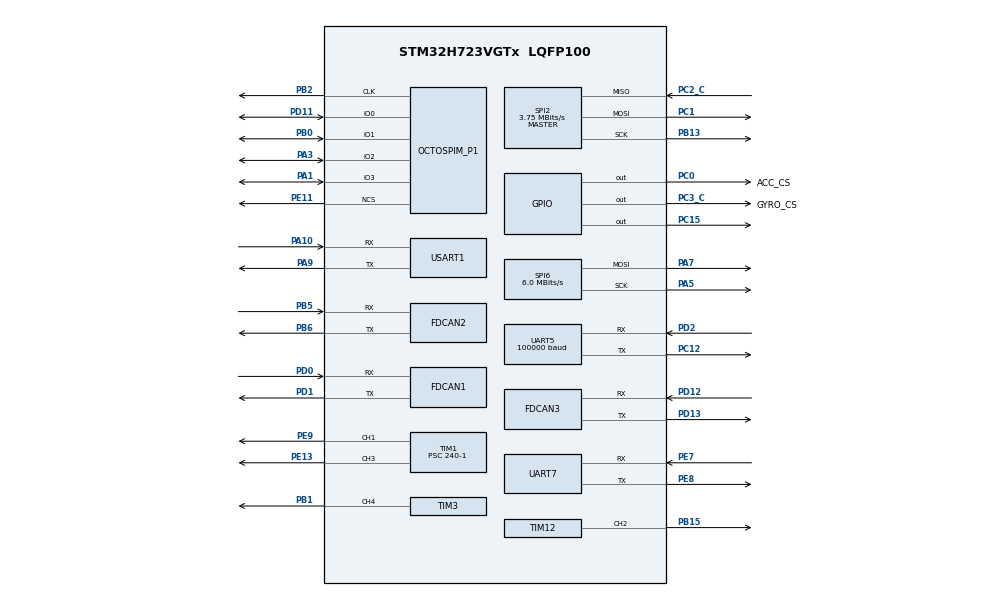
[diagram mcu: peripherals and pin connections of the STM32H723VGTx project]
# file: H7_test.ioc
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CORTEX_M7.CPU_DCache=Disabled
CORTEX_M7.CPU_ICache=Enabled
CORTEX_M7.MPU_Control=__NULL
CORTEX_M7.default_mode_Activation=0
Dma.Request0=UART5_RX
Dma.Request1=USART1_RX
Dma.Request2=UART7_TX
Dma.UART5_RX.0.Direction=DMA_PERIPH_TO_MEMORY
Dma.UART5_RX.0.EventEnable=DISABLE
Dma.UART5_RX.0.FIFOMode=DMA_FIFOMODE_DISABLE
Dma.UART5_RX.0.Instance=DMA1_Stream5
Dma.UART5_RX.0.MemDataAlignment=DMA_MDATAALIGN_BYTE
Dma.UART5_RX.0.MemInc=DMA_MINC_ENABLE
Dma.UART5_RX.0.Mode=DMA_NORMAL
Dma.UART5_RX.0.PeriphDataAlignment=DMA_PDATAALIGN_BYTE
Dma.UART5_RX.0.PeriphInc=DMA_PINC_DISABLE
Dma.UART5_RX.0.Polarity=HAL_DMAMUX_REQ_GEN_RISING
Dma.UART5_RX.0.Priority=DMA_PRIORITY_LOW
Dma.UART5_RX.0.RequestNumber=1
Dma.UART5_RX.0.SignalID=NONE
Dma.UART5_RX.0.SyncEnable=DISABLE
Dma.UART5_RX.0.SyncPolarity=HAL_DMAMUX_SYNC_NO_EVENT
Dma.UART5_RX.0.SyncRequestNumber=1
Dma.UART5_RX.0.SyncSignalID=NONE
Dma.UART7_TX.2.Direction=DMA_MEMORY_TO_PERIPH
Dma.UART7_TX.2.EventEnable=DISABLE
Dma.UART7_TX.2.FIFOMode=DMA_FIFOMODE_DISABLE
Dma.UART7_TX.2.Instance=DMA1_Stream2
Dma.UART7_TX.2.MemDataAlignment=DMA_MDATAALIGN_BYTE
Dma.UART7_TX.2.MemInc=DMA_MINC_ENABLE
Dma.UART7_TX.2.Mode=DMA_NORMAL
Dma.UART7_TX.2.PeriphDataAlignment=DMA_PDATAALIGN_BYTE
Dma.UART7_TX.2.PeriphInc=DMA_PINC_DISABLE
Dma.UART7_TX.2.Polarity=HAL_DMAMUX_REQ_GEN_RISING
Dma.UART7_TX.2.Priority=DMA_PRIORITY_HIGH
Dma.UART7_TX.2.RequestNumber=1
Dma.UART7_TX.2.SignalID=NONE
Dma.UART7_TX.2.SyncEnable=DISABLE
Dma.UART7_TX.2.SyncPolarity=HAL_DMAMUX_SYNC_NO_EVENT
Dma.UART7_TX.2.SyncRequestNumber=1
Dma.UART7_TX.2.SyncSignalID=NONE
Dma.USART1_RX.1.Direction=DMA_PERIPH_TO_MEMORY
Dma.USART1_RX.1.EventEnable=DISABLE
Dma.USART1_RX.1.FIFOMode=DMA_FIFOMODE_DISABLE
Dma.USART1_RX.1.Instance=DMA2_Stream1
Dma.USART1_RX.1.MemDataAlignment=DMA_MDATAALIGN_BYTE
Dma.USART1_RX.1.MemInc=DMA_MINC_ENABLE
Dma.USART1_RX.1.Mode=DMA_NORMAL
Dma.USART1_RX.1.PeriphDataAlignment=DMA_PDATAALIGN_BYTE
Dma.USART1_RX.1.PeriphInc=DMA_PINC_DISABLE
Dma.USART1_RX.1.Polarity=HAL_DMAMUX_REQ_GEN_RISING
Dma.USART1_RX.1.Priority=DMA_PRIORITY_HIGH
Dma.USART1_RX.1.RequestNumber=1
Dma.USART1_RX.1.SignalID=NONE
Dma.USART1_RX.1.SyncEnable=DISABLE
Dma.USART1_RX.1.SyncPolarity=HAL_DMAMUX_SYNC_NO_EVENT
Dma.USART1_RX.1.SyncRequestNumber=1
Dma.USART1_RX.1.SyncSignalID=NONE
FDCAN1.CalculateBaudRateNominal=1000000
FDCAN1.CalculateTimeBitNominal=1000
FDCAN1.CalculateTimeQuantumNominal=200.0
FDCAN1.Mode=FDCAN_MODE_NORMAL
FDCAN1.NominalPrescaler=24
FDCAN1.RxFifo0ElmtsNbr=32
FDCAN1.StdFiltersNbr=1
FDCAN1.TxFifoQueueElmtsNbr=32
FDCAN2.CalculateBaudRateNominal=1000000
FDCAN2.CalculateTimeBitNominal=1000
FDCAN2.CalculateTimeQuantumNominal=200.0
FDCAN2.MessageRAMOffset=0x406
FDCAN2.NominalPrescaler=24
FDCAN2.RxFifo0ElmtsNbr=32
FDCAN2.StdFiltersNbr=1
FDCAN2.TxFifoQueueElmtsNbr=32
FDCAN3.CalculateBaudRateNominal=1000000
FDCAN3.CalculateTimeBitNominal=1000
FDCAN3.CalculateTimeQuantumNominal=200.0
FDCAN3.MessageRAMOffset=0x812
FDCAN3.NominalPrescaler=24
FDCAN3.RxFifo0ElmtsNbr=32
FDCAN3.StdFiltersNbr=1
FDCAN3.TxFifoQueueElmtsNbr=32
FREERTOS.Tasks01=defaultTask,24,64,StartDefaultTask,Default,NULL,Dynamic,NULL,NULL;Ws2812_task,9,64,ws2812_task,As external,NULL,Dynamic,NULL,NULL;INS_task,11,128,ins_task,As external,NULL,Dynamic,NULL,NULL;BUZZER_task,9,64,buzzer_task,As external,NULL,Dynamic,NULL,NULL;CK_TIMEOUT_TASK,9,64,CK_Timeout_task,As external,NULL,Dynamic,NULL,NULL;CP_TASK,11,128,CP_task,As external,NULL,Dynamic,NULL,NULL;GYM_TASK,13,256,Gym_task,As external,NULL,Dynamic,NULL,NULL;UI_TASK,12,128,UI_task,As external,NULL,Dynamic,NULL,NULL;SERVER_TASK,12,64,Servos_task,As external,NULL,Dynamic,NULL,NULL
FREERTOS.configENABLE_FPU=1
FREERTOS.configMINIMAL_STACK_SIZE=0x40
FREERTOS.configUSE_OS2_MUTEX=0
FREERTOS.configUSE_OS2_TIMER=0
Mcu.Family=STM32H7
Mcu.Name=STM32H723VGTx
Mcu.Package=LQFP100
NVIC.DMA1_Stream2_IRQn=true\:5\:0\:false\:false\:true\:false\:false\:true\:true
NVIC.DMA1_Stream5_IRQn=true\:0\:0\:false\:false\:true\:false\:false\:true\:true
NVIC.DMA2_Stream1_IRQn=true\:0\:0\:false\:false\:true\:false\:false\:true\:true
NVIC.FDCAN1_IT0_IRQn=true\:1\:0\:true\:false\:true\:false\:true\:true\:true
NVIC.FDCAN1_IT1_IRQn=true\:1\:0\:true\:false\:true\:false\:true\:true\:true
NVIC.FDCAN2_IT0_IRQn=true\:1\:0\:true\:false\:true\:false\:true\:true\:true
NVIC.FDCAN2_IT1_IRQn=true\:1\:0\:true\:false\:true\:false\:true\:true\:true
NVIC.FDCAN3_IT0_IRQn=true\:1\:0\:true\:false\:true\:false\:true\:true\:true
NVIC.FDCAN3_IT1_IRQn=true\:1\:0\:true\:false\:true\:false\:true\:true\:true
NVIC.PriorityGroup=NVIC_PRIORITYGROUP_4
NVIC.TIM23_IRQn=true\:15\:0\:false\:false\:true\:false\:false\:true\:true
NVIC.TimeBase=TIM23_IRQn
NVIC.TimeBaseIP=TIM23
NVIC.UART5_IRQn=true\:1\:0\:true\:false\:true\:false\:true\:true\:true
NVIC.USART1_IRQn=true\:1\:0\:true\:false\:true\:false\:true\:true\:true
OCTOSPI2.ClockMode=HAL_OSPI_CLOCK_MODE_3
OCTOSPI2.ClockPrescaler=3
OCTOSPI2.DeviceSize=23
OCTOSPI2.DeviceType=SPI_DEVICE_FLASH
OCTOSPI2.FifoThreshold=8
OCTOSPI2.SampleShifting=HAL_OSPI_SAMPLE_SHIFTING_HALFCYCLE
PA1.Mode=OCTOSPI2_IOL_Port1L
PA1.Signal=OCTOSPIM_P1_IO3
PA10.GPIO_PuPd=GPIO_PULLUP
PA10.GPIO_Speed=GPIO_SPEED_FREQ_HIGH
PA10.Mode=Asynchronous
PA10.Signal=USART1_RX
PA13(JTMS/SWDIO).Mode=Serial_Wire
PA13(JTMS/SWDIO).Signal=DEBUG_JTMS-SWDIO
PA14(JTCK/SWCLK).Mode=Serial_Wire
PA14(JTCK/SWCLK).Signal=DEBUG_JTCK-SWCLK
PA3.Mode=OCTOSPI2_IOL_Port1L
PA3.Signal=OCTOSPIM_P1_IO2
PA5.GPIO_Speed=GPIO_SPEED_FREQ_VERY_HIGH
PA5.Mode=TX_Only_Simplex_Unidirect_Master
PA5.Signal=SPI6_SCK
PA7.GPIO_Speed=GPIO_SPEED_FREQ_VERY_HIGH
PA7.Mode=TX_Only_Simplex_Unidirect_Master
PA7.Signal=SPI6_MOSI
PA9.GPIO_PuPd=GPIO_PULLUP
PA9.GPIO_Speed=GPIO_SPEED_FREQ_HIGH
PA9.Mode=Asynchronous
PA9.Signal=USART1_TX
PB0.Mode=OCTOSPI2_IOL_Port1L
PB0.Signal=OCTOSPIM_P1_IO1
PB1.Signal=S_TIM3_CH4
PB13.GPIO_Speed=GPIO_SPEED_FREQ_VERY_HIGH
PB13.Mode=Full_Duplex_Master
PB13.Signal=SPI2_SCK
PB15.GPIO_Speed=GPIO_SPEED_FREQ_VERY_HIGH
PB15.Signal=S_TIM12_CH2
PB2.Mode=O2_P1_CLK
PB2.Signal=OCTOSPIM_P1_CLK
PB5.Mode=FDCAN_Activate
PB5.Signal=FDCAN2_RX
PB6.Mode=FDCAN_Activate
PB6.Signal=FDCAN2_TX
PC0.GPIO_Label=ACC_CS
PC0.GPIO_Speed=GPIO_SPEED_FREQ_VERY_HIGH
PC0.PinState=GPIO_PIN_SET
PC0.Signal=GPIO_Output
PC1.GPIO_Speed=GPIO_SPEED_FREQ_VERY_HIGH
PC1.Mode=Full_Duplex_Master
PC1.Signal=SPI2_MOSI
PC12.Mode=Asynchronous
PC12.Signal=UART5_TX
PC15-OSC32_OUT.Signal=GPIO_Output
PC2_C.GPIO_Speed=GPIO_SPEED_FREQ_VERY_HIGH
PC2_C.Mode=Full_Duplex_Master
PC2_C.Signal=SPI2_MISO
PC3_C.GPIO_Label=GYRO_CS
PC3_C.GPIO_Speed=GPIO_SPEED_FREQ_VERY_HIGH
PC3_C.PinState=GPIO_PIN_SET
PC3_C.Signal=GPIO_Output
PD0.GPIO_Speed=GPIO_SPEED_FREQ_VERY_HIGH
PD0.Mode=FDCAN_Activate
PD0.Signal=FDCAN1_RX
PD1.GPIO_Speed=GPIO_SPEED_FREQ_VERY_HIGH
PD1.Mode=FDCAN_Activate
PD1.Signal=FDCAN1_TX
PD11.Mode=OCTOSPI2_IOL_Port1L
PD11.Signal=OCTOSPIM_P1_IO0
PD12.Mode=FDCAN_Activate
PD12.Signal=FDCAN3_RX
PD13.Mode=FDCAN_Activate
PD13.Signal=FDCAN3_TX
PD2.GPIO_Speed=GPIO_SPEED_FREQ_LOW
PD2.Mode=Asynchronous
PD2.Signal=UART5_RX
PE11.Mode=OCTOSPI2_Port1_NCS
PE11.Signal=OCTOSPIM_P1_NCS
PE13.Signal=S_TIM1_CH3
PE7.Mode=Asynchronous
PE7.Signal=UART7_RX
PE8.Mode=Asynchronous
PE8.Signal=UART7_TX
PE9.Signal=S_TIM1_CH1
PH0-OSC_IN.Mode=HSE-External-Oscillator
PH0-OSC_IN.Signal=RCC_OSC_IN
PH1-OSC_OUT.Mode=HSE-External-Oscillator
PH1-OSC_OUT.Signal=RCC_OSC_OUT
ProjectManager.HeapSize=0x200
ProjectManager.StackSize=0x800
ProjectManager.TargetToolchain=MDK-ARM V5.27
RCC.ADCFreq_Value=48375000
RCC.APB1Freq_Value=120000000
RCC.APB2Freq_Value=120000000
RCC.APB3Freq_Value=120000000
RCC.APB4Freq_Value=120000000
RCC.CortexFreq_Value=480000000
RCC.D1PPRE=RCC_APB3_DIV2
RCC.D2PPRE1=RCC_APB1_DIV2
RCC.D2PPRE2=RCC_APB2_DIV2
RCC.D3PPRE=RCC_APB4_DIV2
RCC.DIVM1=2
RCC.DIVN1=40
RCC.DIVP1=1
RCC.DIVQ1=4
RCC.EnbaleCSS=true
RCC.HCLKFreq_Value=240000000
RCC.HPRE=RCC_HCLK_DIV2
RCC.HSE_VALUE=24000000
RCC.PLL3FRACN=0
RCC.PLLFRACN=0
RCC.PLLSourceVirtual=RCC_PLLSOURCE_HSE
RCC.SPI6CLockSelection=RCC_SPI6CLKSOURCE_HSE
RCC.SYSCLKFreq_VALUE=480000000
RCC.SYSCLKSource=RCC_SYSCLKSOURCE_PLLCLK
RCC.USBFreq_Value=120000000
SH.S_TIM12_CH2.0=TIM12_CH2,PWM Generation2 CH2
SH.S_TIM1_CH1.0=TIM1_CH1,PWM Generation1 CH1
SH.S_TIM1_CH3.0=TIM1_CH3,PWM Generation3 CH3
SH.S_TIM3_CH4.0=TIM3_CH4,PWM Generation4 CH4
SPI2.BaudRatePrescaler=SPI_BAUDRATEPRESCALER_32
SPI2.CLKPhase=SPI_PHASE_2EDGE
SPI2.CLKPolarity=SPI_POLARITY_HIGH
SPI2.CalculateBaudRate=3.75 MBits/s
SPI2.DataSize=SPI_DATASIZE_8BIT
SPI2.Direction=SPI_DIRECTION_2LINES
SPI2.Mode=SPI_MODE_MASTER
SPI2.VirtualType=VM_MASTER
SPI6.BaudRatePrescaler=SPI_BAUDRATEPRESCALER_4
SPI6.CLKPhase=SPI_PHASE_2EDGE
SPI6.CalculateBaudRate=6.0 MBits/s
SPI6.DataSize=SPI_DATASIZE_8BIT
SPI6.Direction=SPI_DIRECTION_2LINES_TXONLY
SPI6.Mode=SPI_MODE_MASTER
SPI6.VirtualType=VM_MASTER
TIM1.Channel-PWM\ Generation1\ CH1=TIM_CHANNEL_1
TIM1.Channel-PWM\ Generation3\ CH3=TIM_CHANNEL_3
TIM1.Period=20000-1
TIM1.Prescaler=240-1
TIM12.Channel-PWM\ Generation2\ CH2=TIM_CHANNEL_2
TIM12.Period=2000-1
TIM12.Prescaler=128-1
TIM3.AutoReloadPreload=TIM_AUTORELOAD_PRELOAD_ENABLE
TIM3.Channel-PWM\ Generation4\ CH4=TIM_CHANNEL_4
TIM3.Period=10000-1
TIM3.Prescaler=24-1
UART5.BaudRate=100000
UART5.Mode=MODE_RX
UART5.Parity=PARITY_EVEN
UART5.StopBits=UART_STOPBITS_2
UART5.WordLength=WORDLENGTH_9B
USART1.VirtualMode-Asynchronous=VM_ASYNC
VP_FREERTOS_VS_CMSIS_V2.Mode=CMSIS_V2
VP_OCTOSPI2_VS_quad.Mode=quad_mode
VP_SYS_VS_tim23.Mode=TIM23
board=custom

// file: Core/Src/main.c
/* USER CODE BEGIN Header */
/**
  ******************************************************************************
  * @file           : main.c
  * @brief          : Main program body
  ******************************************************************************
  * @attention
  *
  * Copyright (c) 2024 STMicroelectronics.
  * All rights reserved.
  *
  * This software is licensed under terms that can be found in the LICENSE file
  * in the root directory of this software component.
  * If no LICENSE file comes with this software, it is provided AS-IS.
  *
  ******************************************************************************
  */
/* USER CODE END Header */
#include "main.h"
#include "cmsis_os.h"
#include "dma.h"
#include "fdcan.h"
#include "octospi.h"
#include "spi.h"
#include "tim.h"
#include "usart.h"
#include "gpio.h"

/* USER CODE BEGIN Includes */
#include "BSP_CAN.h"
#include "REMOTE_task.h"
#include "cp_usart.h"
/* USER CODE END Includes */

void SystemClock_Config(void);
void MX_FREERTOS_Init(void);
/* USER CODE BEGIN PFP */
extern uint8_t usart3_rx_data_buf[REMOTE_RECEVER_LEN+5];
extern uint8_t uart6_rx_data_buf[USART6_DMA_RX_DATA_LEN];
/* USER CODE END PFP */

int main(void)
{

  /* Enable the CPU Cache */

  /* Enable I-Cache---------------------------------------------------------*/
  SCB_EnableICache();

  /* MCU Configuration--------------------------------------------------------*/

  /* Reset of all peripherals, Initializes the Flash interface and the Systick. */
  HAL_Init();

  /* Configure the system clock */
  SystemClock_Config();

  /* Initialize all configured peripherals */
  MX_GPIO_Init();
  MX_DMA_Init();
  MX_OCTOSPI2_Init();
  MX_FDCAN1_Init();
  MX_FDCAN2_Init();
  MX_FDCAN3_Init();
  MX_SPI2_Init();
  MX_TIM3_Init();
  MX_TIM12_Init();
  MX_SPI6_Init();
  MX_UART5_Init();
  MX_USART1_UART_Init();
  MX_TIM1_Init();
  MX_UART7_Init();
  /* USER CODE BEGIN 2 */
  while(HAL_UARTEx_ReceiveToIdle_DMA(&huart1,uart6_rx_data_buf,USART6_DMA_RX_DATA_LEN) != HAL_OK);  // 串口1 DMA 开启接受（裁判系统）
  can_bsp_init();
  HAL_UARTEx_ReceiveToIdle_DMA(&huart5,usart3_rx_data_buf,REMOTE_RECEVER_LEN);    // 串口5 DMA 开始接受（遥控器）

  /* USER CODE END 2 */

  /* Init scheduler */
  osKernelInitialize();

  /* Call init function for freertos objects (in cmsis_os2.c) */
  MX_FREERTOS_Init();

  /* Start scheduler */
  osKernelStart();

  /* We should never get here as control is now taken by the scheduler */

  /* Infinite loop */
  while (1)
  {

  }
}

void SystemClock_Config(void)
{
  RCC_OscInitTypeDef RCC_OscInitStruct = {0};
  RCC_ClkInitTypeDef RCC_ClkInitStruct = {0};

  /** Supply configuration update enable
  */
  HAL_PWREx_ConfigSupply(PWR_LDO_SUPPLY);

  /** Configure the main internal regulator output voltage
  */
  __HAL_PWR_VOLTAGESCALING_CONFIG(PWR_REGULATOR_VOLTAGE_SCALE0);

  while(!__HAL_PWR_GET_FLAG(PWR_FLAG_VOSRDY)) {}

  /** Initializes the RCC Oscillators according to the specified parameters
  * in the RCC_OscInitTypeDef structure.
  */
  RCC_OscInitStruct.OscillatorType = RCC_OSCILLATORTYPE_HSE;
  RCC_OscInitStruct.HSEState = RCC_HSE_ON;
  RCC_OscInitStruct.PLL.PLLState = RCC_PLL_ON;
  RCC_OscInitStruct.PLL.PLLSource = RCC_PLLSOURCE_HSE;
  RCC_OscInitStruct.PLL.PLLM = 2;
  RCC_OscInitStruct.PLL.PLLN = 40;
  RCC_OscInitStruct.PLL.PLLP = 1;
  RCC_OscInitStruct.PLL.PLLQ = 4;
  RCC_OscInitStruct.PLL.PLLR = 2;
  RCC_OscInitStruct.PLL.PLLRGE = RCC_PLL1VCIRANGE_3;
  RCC_OscInitStruct.PLL.PLLVCOSEL = RCC_PLL1VCOWIDE;
  RCC_OscInitStruct.PLL.PLLFRACN = 0;
  if (HAL_RCC_OscConfig(&RCC_OscInitStruct) != HAL_OK)
  {
    Error_Handler();
  }

  /** Initializes the CPU, AHB and APB buses clocks
  */
  RCC_ClkInitStruct.ClockType = RCC_CLOCKTYPE_HCLK|RCC_CLOCKTYPE_SYSCLK
                              |RCC_CLOCKTYPE_PCLK1|RCC_CLOCKTYPE_PCLK2
                              |RCC_CLOCKTYPE_D3PCLK1|RCC_CLOCKTYPE_D1PCLK1;
  RCC_ClkInitStruct.SYSCLKSource = RCC_SYSCLKSOURCE_PLLCLK;
  RCC_ClkInitStruct.SYSCLKDivider = RCC_SYSCLK_DIV1;
  RCC_ClkInitStruct.AHBCLKDivider = RCC_HCLK_DIV2;
  RCC_ClkInitStruct.APB3CLKDivider = RCC_APB3_DIV2;
  RCC_ClkInitStruct.APB1CLKDivider = RCC_APB1_DIV2;
  RCC_ClkInitStruct.APB2CLKDivider = RCC_APB2_DIV2;
  RCC_ClkInitStruct.APB4CLKDivider = RCC_APB4_DIV2;

  if (HAL_RCC_ClockConfig(&RCC_ClkInitStruct, FLASH_LATENCY_3) != HAL_OK)
  {
    Error_Handler();
  }

  /** Enables the Clock Security System
  */
  HAL_RCC_EnableCSS();
}

void HAL_TIM_PeriodElapsedCallback(TIM_HandleTypeDef *htim)
{
  if (htim->Instance == TIM23) {
    HAL_IncTick();
  }
}

void Error_Handler(void)
{
  __disable_irq();
  while (1)
  {
  }
}

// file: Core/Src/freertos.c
/* USER CODE BEGIN Header */
/**
  ******************************************************************************
  * File Name          : freertos.c
  * Description        : Code for freertos applications
  ******************************************************************************
  * @attention
  *
  * Copyright (c) 2024 STMicroelectronics.
  * All rights reserved.
  *
  * This software is licensed under terms that can be found in the LICENSE file
  * in the root directory of this software component.
  * If no LICENSE file comes with this software, it is provided AS-IS.
  *
  ******************************************************************************
  */
/* USER CODE END Header */

#include "FreeRTOS.h"
#include "task.h"
#include "main.h"
#include "cmsis_os.h"

/* USER CODE BEGIN Includes */
#include "WS2812_task.h"

/* USER CODE END Includes */

/* Definitions for defaultTask */
osThreadId_t defaultTaskHandle;
const osThreadAttr_t defaultTask_attributes = {
  .name = "defaultTask",
  .stack_size = 64 * 4,
  .priority = (osPriority_t) osPriorityNormal,
};
/* Definitions for Ws2812_task */
osThreadId_t Ws2812_taskHandle;
const osThreadAttr_t Ws2812_task_attributes = {
  .name = "Ws2812_task",
  .stack_size = 64 * 4,
  .priority = (osPriority_t) osPriorityLow1,
};
/* Definitions for INS_task */
osThreadId_t INS_taskHandle;
const osThreadAttr_t INS_task_attributes = {
  .name = "INS_task",
  .stack_size = 128 * 4,
  .priority = (osPriority_t) osPriorityLow3,
};
/* Definitions for BUZZER_task */
osThreadId_t BUZZER_taskHandle;
const osThreadAttr_t BUZZER_task_attributes = {
  .name = "BUZZER_task",
  .stack_size = 64 * 4,
  .priority = (osPriority_t) osPriorityLow1,
};
/* Definitions for CK_TIMEOUT_TASK */
osThreadId_t CK_TIMEOUT_TASKHandle;
const osThreadAttr_t CK_TIMEOUT_TASK_attributes = {
  .name = "CK_TIMEOUT_TASK",
  .stack_size = 64 * 4,
  .priority = (osPriority_t) osPriorityLow1,
};
/* Definitions for CP_TASK */
osThreadId_t CP_TASKHandle;
const osThreadAttr_t CP_TASK_attributes = {
  .name = "CP_TASK",
  .stack_size = 128 * 4,
  .priority = (osPriority_t) osPriorityLow3,
};
/* Definitions for GYM_TASK */
osThreadId_t GYM_TASKHandle;
const osThreadAttr_t GYM_TASK_attributes = {
  .name = "GYM_TASK",
  .stack_size = 256 * 4,
  .priority = (osPriority_t) osPriorityLow5,
};
/* Definitions for UI_TASK */
osThreadId_t UI_TASKHandle;
const osThreadAttr_t UI_TASK_attributes = {
  .name = "UI_TASK",
  .stack_size = 128 * 4,
  .priority = (osPriority_t) osPriorityLow4,
};
/* Definitions for SERVER_TASK */
osThreadId_t SERVER_TASKHandle;
const osThreadAttr_t SERVER_TASK_attributes = {
  .name = "SERVER_TASK",
  .stack_size = 64 * 4,
  .priority = (osPriority_t) osPriorityLow4,
};

void StartDefaultTask(void *argument);
extern void ws2812_task(void *argument);
extern void ins_task(void *argument);
extern void buzzer_task(void *argument);
extern void CK_Timeout_task(void *argument);
extern void CP_task(void *argument);
extern void Gym_task(void *argument);
extern void UI_task(void *argument);
extern void Servos_task(void *argument);

void MX_FREERTOS_Init(void); /* (MISRA C 2004 rule 8.1) */

void MX_FREERTOS_Init(void) {

  /* Create the thread(s) */
  /* creation of defaultTask */
  defaultTaskHandle = osThreadNew(StartDefaultTask, NULL, &defaultTask_attributes);

  /* creation of Ws2812_task */
  Ws2812_taskHandle = osThreadNew(ws2812_task, NULL, &Ws2812_task_attributes);

  /* creation of INS_task */
  INS_taskHandle = osThreadNew(ins_task, NULL, &INS_task_attributes);

  /* creation of BUZZER_task */
  BUZZER_taskHandle = osThreadNew(buzzer_task, NULL, &BUZZER_task_attributes);

  /* creation of CK_TIMEOUT_TASK */
  CK_TIMEOUT_TASKHandle = osThreadNew(CK_Timeout_task, NULL, &CK_TIMEOUT_TASK_attributes);

  /* creation of CP_TASK */
  CP_TASKHandle = osThreadNew(CP_task, NULL, &CP_TASK_attributes);

  /* creation of GYM_TASK */
  GYM_TASKHandle = osThreadNew(Gym_task, NULL, &GYM_TASK_attributes);

  /* creation of UI_TASK */
  UI_TASKHandle = osThreadNew(UI_task, NULL, &UI_TASK_attributes);

  /* creation of SERVER_TASK */
  SERVER_TASKHandle = osThreadNew(Servos_task, NULL, &SERVER_TASK_attributes);

}

void StartDefaultTask(void *argument)
{
  for(;;)
  {
    osDelay(1);
  }
}
